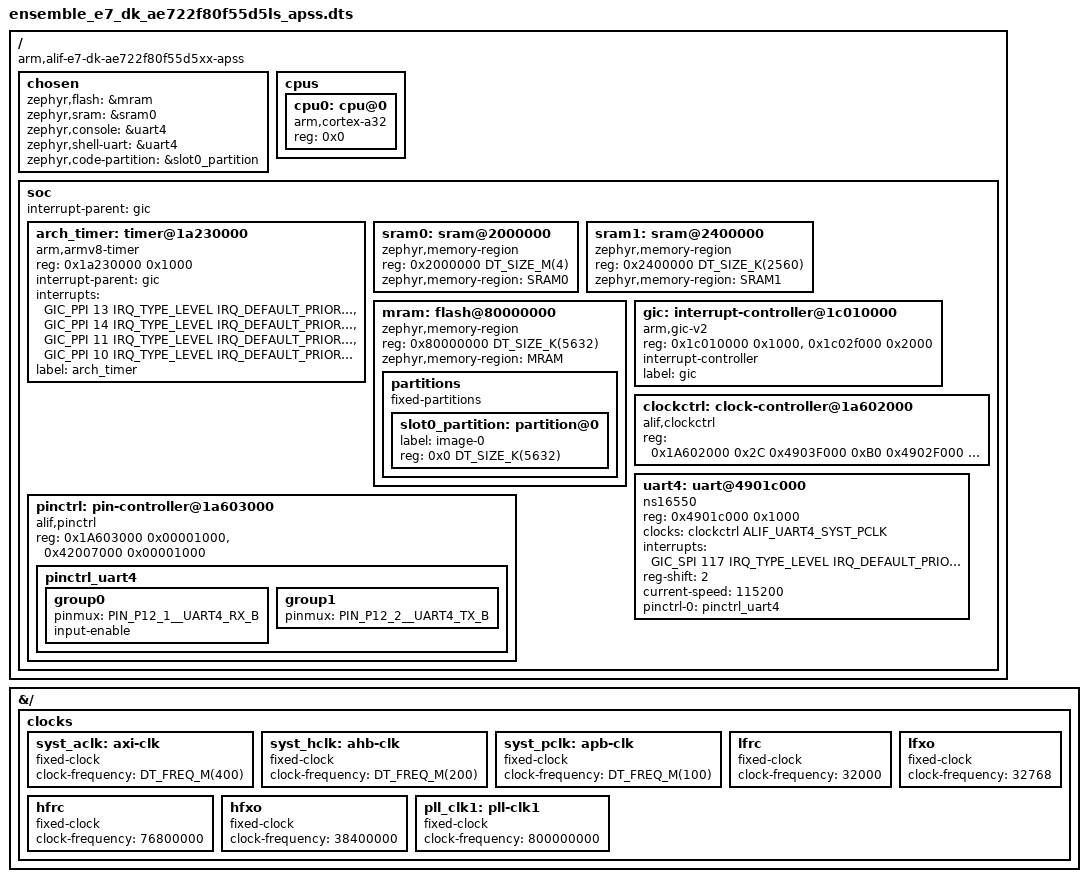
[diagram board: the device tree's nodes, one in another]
/* Copyright (c) 2025 Alif Semiconductor
 *
 * SPDX-License-Identifier: Apache-2.0
 */

/dts-v1/;


#include <freq.h>
#include <arm64/armv8-a.dtsi>
#include <mem.h>
#include <zephyr/dt-bindings/interrupt-controller/arm-gic.h>
#include <zephyr/dt-bindings/pinctrl/ensemble-pinctrl.h>
#include <zephyr/dt-bindings/clock/alif-ensemble-clocks.h>

/ {
	compatible = "arm,alif-e7-dk-ae722f80f55d5xx-apss";
	#address-cells = <1>;
	#size-cells = <1>;

	chosen {
		zephyr,flash = &mram;
		zephyr,sram = &sram0;
		zephyr,console = &uart4;
		zephyr,shell-uart = &uart4;
		zephyr,code-partition = &slot0_partition;
	};

	cpus {
		#address-cells = <1>;
		#size-cells = <0>;
		cpu0: cpu@0 {
			device_type = "cpu";
			compatible = "arm,cortex-a32";
			reg = <0x0>;
		};
	};

	soc {
		#address-cells = <1>;
		#size-cells = <1>;
		interrupt-parent = <&gic>;

		arch_timer: timer@1a230000 {
			compatible = "arm,armv8-timer";
			reg = <0x1a230000 0x1000>;
			interrupt-parent = <&gic>;
			interrupts = <GIC_PPI 13 IRQ_TYPE_LEVEL IRQ_DEFAULT_PRIORITY>,
				     <GIC_PPI 14 IRQ_TYPE_LEVEL IRQ_DEFAULT_PRIORITY>,
				     <GIC_PPI 11 IRQ_TYPE_LEVEL IRQ_DEFAULT_PRIORITY>,
				     <GIC_PPI 10 IRQ_TYPE_LEVEL IRQ_DEFAULT_PRIORITY>;
			label = "arch_timer";
			status = "okay";
		};

		sram0: sram@2000000 {
			compatible = "zephyr,memory-region", "mmio-sram";
			reg = <0x2000000 DT_SIZE_M(4)>;
			zephyr,memory-region = "SRAM0";
		};

		sram1: sram@2400000 {
			compatible = "zephyr,memory-region", "mmio-sram";
			reg = <0x2400000 DT_SIZE_K(2560)>;
			zephyr,memory-region = "SRAM1";
		};

		mram: flash@80000000 {
			compatible = "zephyr,memory-region", "soc-nv-flash";
			reg = <0x80000000 DT_SIZE_K(5632)>;
			zephyr,memory-region = "MRAM";

			#address-cells = <1>;
			#size-cells = <1>;
			ranges = <0x0 0x80000000 DT_SIZE_K(5632)>;
		};

		gic: interrupt-controller@1c010000 {
			compatible = "arm,gic-v2", "arm,gic";
			reg = <0x1c010000 0x1000>,
			      <0x1c02f000 0x2000>;
			interrupt-controller;
			#interrupt-cells = <4>;
			label = "gic";
			status = "okay";
		};

		clockctrl: clock-controller@1a602000 {
			compatible = "alif,clockctrl";
			reg = <0x1A602000 0x2C
				0x4903F000 0xB0
				0x4902F000 0xBC
				0x1A604000 0x44
				0x1A609000 0x14
				0x43007000 0x2C
				0x400F0000 0x14>;
			reg-names = "cgu",
				    "clkctl_per_mst",
				    "clkctl_per_slv",
				    "aon",
				    "vbat",
				    "m55he_cfg",
				    "m55hp_cfg";
			#clock-cells = <1>;
			status = "okay";
		};

		pinctrl: pin-controller@1a603000 {
			compatible = "alif,pinctrl";
			reg = <0x1A603000 0x00001000>, <0x42007000 0x00001000>;
			reg-names = "pinctrl", "lpgpio_pinctrl";

			pinctrl_uart4: pinctrl_uart4 {
				group0 {
					pinmux = <PIN_P12_1__UART4_RX_B>;
					input-enable;
				};

				group1 {
					pinmux = <PIN_P12_2__UART4_TX_B>;
				};
			};
		};

		uart4: uart@4901c000 {
			compatible = "ns16550";
			reg = <0x4901c000 0x1000>;
			clocks = <&clockctrl ALIF_UART4_SYST_PCLK>;
			interrupts = <GIC_SPI 117 IRQ_TYPE_LEVEL IRQ_DEFAULT_PRIORITY>;
			reg-shift = <2>;
			current-speed = <115200>;
			pinctrl-0 = <&pinctrl_uart4>;
			pinctrl-names = "default";
			status = "okay";
		};
	};
};

&{/} {
	clocks {
		syst_aclk: axi-clk {
			compatible = "fixed-clock";
			clock-frequency = <DT_FREQ_M(400)>;
			#clock-cells = <0>;
		};

		syst_hclk: ahb-clk {
			compatible = "fixed-clock";
			clock-frequency = <DT_FREQ_M(200)>;
			#clock-cells = <0>;
		};

		syst_pclk: apb-clk {
			compatible = "fixed-clock";
			clock-frequency = <DT_FREQ_M(100)>;
			#clock-cells = <0>;
		};
		lfrc: lfrc {
			compatible = "fixed-clock";
			clock-frequency = <32000>;
			status = "okay";
			#clock-cells = <0>;
		};
		lfxo: lfxo {
			compatible = "fixed-clock";
			clock-frequency = <32768>;
			status = "okay";
			#clock-cells = <0>;
		};
		hfrc: hfrc {
			compatible = "fixed-clock";
			clock-frequency = <76800000>;
			status = "okay";
			#clock-cells = <0>;
		};
		hfxo: hfxo {
			compatible = "fixed-clock";
			clock-frequency = <38400000>;
			status = "okay";
			#clock-cells = <0>;
		};
		pll_clk1: pll-clk1 {
			compatible = "fixed-clock";
			clock-frequency = <800000000>;
			status = "okay";
			#clock-cells = <0>;
		};
	};
};

&mram {
	partitions {
		compatible = "fixed-partitions";
		#address-cells = <1>;
		#size-cells = <1>;
		ranges;

		slot0_partition: partition@0 {
			label = "image-0";
			reg = <0x0 DT_SIZE_K(5632)>;
		};
	};
};
